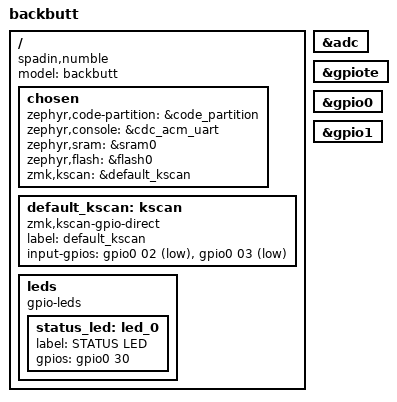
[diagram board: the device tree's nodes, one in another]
#include <nordic/nrf52840_qiaa.dtsi>

/ {
    model = "backbutt";
    compatible = "spadin,numble";

    chosen {
        zephyr,code-partition = &code_partition;
        zephyr,console = &cdc_acm_uart;
        zephyr,sram = &sram0;
        zephyr,flash = &flash0;
        zmk,kscan = &default_kscan;
    };

    default_kscan: kscan {
        compatible = "zmk,kscan-gpio-direct";
        label = "default_kscan";

        input-gpios =
            <&gpio0 02 (GPIO_ACTIVE_LOW | GPIO_PULL_UP)>,
            <&gpio0 03 (GPIO_ACTIVE_LOW | GPIO_PULL_UP)>;
    };


    leds {
        compatible = "gpio-leds";

        status_led: led_0 {
            label = "STATUS LED";
            gpios = <&gpio0 30 (GPIO_ACTIVE_LOW> | GPIO_PULL_UP);
        };
    };

};

&adc {
    status = "okay";
};

&gpiote {
    status = "okay";
};

&gpio0 {
    status = "okay";
};

&gpio1 {
    status = "okay";
};
